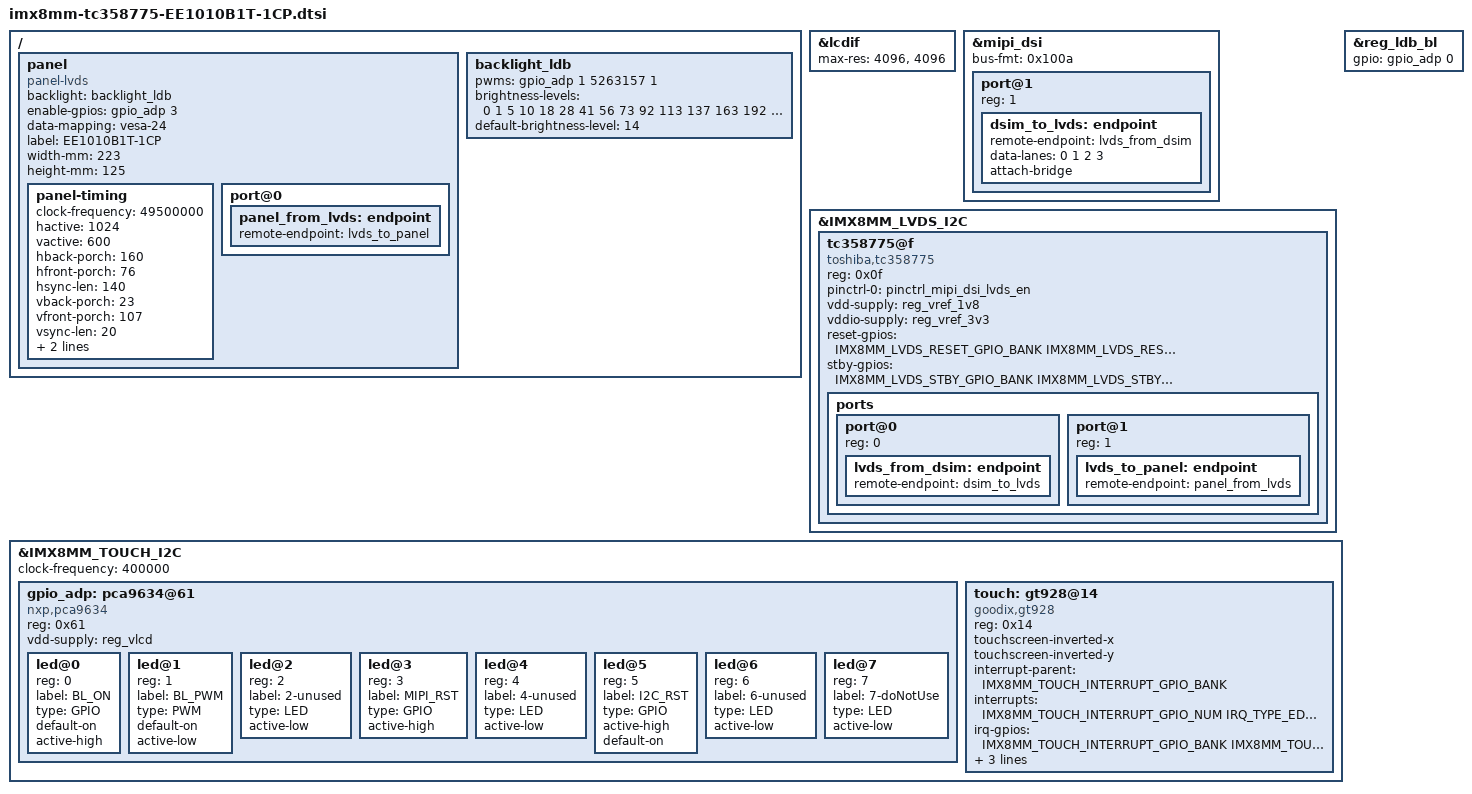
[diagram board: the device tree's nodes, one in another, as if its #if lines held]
/*
 * Copyright (C) 2024 F&S Elektronik Systeme GmbH
 *
 * This program is free software; you can redistribute it and/or modify
 * it under the terms of the GNU General Public License version 2 as
 * published by the Free Software Foundation.
 */

&lcdif {
        status = "okay";
        /* important to overwrite max-res otherwise DRM lcdif will fail to
         * find a suitable connector
         */
        max-res = <4096>, <4096>;
};

&mipi_dsi {
        status = "okay";
        bus-fmt = <0x100a>;
        port@1 {
                reg = <1>;
                dsim_to_lvds: endpoint {
                        remote-endpoint = <&lvds_from_dsim>;
                        data-lanes = <0 1 2 3>;
                        attach-bridge;
                };
        };
};

&IMX8MM_LVDS_I2C {
        tc358775@f {
                compatible = "toshiba,tc358775";
                reg = <0x0f>;
                pinctrl-names = "default";
                pinctrl-0 = <&pinctrl_mipi_dsi_lvds_en>;
                vdd-supply = <&reg_vref_1v8>;
                vddio-supply = <&reg_vref_3v3>;

                reset-gpios = <&IMX8MM_LVDS_RESET_GPIO_BANK IMX8MM_LVDS_RESET_GPIO_NUM GPIO_ACTIVE_LOW>;
#ifdef IMX8MM_LVDS_STBY_GPIO_BANK
                stby-gpios  = <&IMX8MM_LVDS_STBY_GPIO_BANK IMX8MM_LVDS_STBY_GPIO_NUM GPIO_ACTIVE_LOW>;
#endif
                ports {
                        #address-cells = <1>;
                        #size-cells = <0>;

                        port@0 {
                                reg = <0>;

                                lvds_from_dsim: endpoint {
                                        remote-endpoint = <&dsim_to_lvds>;
                                };
                        };

                        port@1 {
                                reg = <1>;

                                lvds_to_panel: endpoint {
                                        remote-endpoint = <&panel_from_lvds>;
                                };
                        };
                };
        };
};

/{
        panel: panel {
			compatible = "panel-lvds";
			backlight = <&backlight_ldb>;
			/* MIPI_RST from board */
			//enable-gpios = <&IMX8MP_MIPI_RESET_GPIO_BANK IMX8MP_MIPI_RESET_GPIO_NUM GPIO_ACTIVE_HIGH>;
			/* Mounting option for MIPI_RST on pca9634 (ADP-LVDS2LVDS2) */
			enable-gpios = <&gpio_adp 3 GPIO_ACTIVE_HIGH>;
			data-mapping = "vesa-24";
			label = "EE1010B1T-1CP";
		            width-mm = <223>;
		            height-mm = <125>;
			status = "okay";

			panel-timing {
				clock-frequency = <49500000>;
				hactive = <1024>;
				vactive = <600>;

				hback-porch = <160>;
				hfront-porch = <76>;
				hsync-len = <140>;
				vback-porch = <23>;
				vfront-porch = <107>;
				vsync-len = <20>;
				pixelclk-active = <0>;
				de-active = <1>;
			};

                port@0 {
                        panel_from_lvds: endpoint {
                                remote-endpoint = <&lvds_to_panel>;
                        };
                };
        };

        backlight_ldb: backlight_ldb {
                pwms = <&gpio_adp 1 5263157 1>;
                brightness-levels = <0 1 5 10 18 28 41 56
                                     73 92 113 137 163 192 222 255>;
                default-brightness-level = <14>;
        };
};

&reg_ldb_bl{
	gpio = <&gpio_adp 0 GPIO_ACTIVE_HIGH>;
};


&IMX8MM_TOUCH_I2C {
	clock-frequency = <400000>;
	gpio_adp: pca9634@61 {
			compatible = "nxp,pca9634";
			reg = <0x61>;
			vdd-supply = <&reg_vlcd>;
			#address-cells = <1>;
			#size-cells = <0>;
			#pwm-cells = <3>;
			#gpio-cells = <2>;
			led@0 {
				reg = <0>;
				label = "BL_ON";
				type = "GPIO";
				default-on;	        /* or: keep-value */
				active-high;
			};
			led@1 {
				reg = <1>;
				label = "BL_PWM";
				type = "PWM";
				default-on;             /* or: keep-value */
				active-low;
			};
			led@2 {
				reg = <2>;
				label = "2-unused";
				type = "LED";
				active-low;
			};
			led@3 {
				reg = <3>;
				label = "MIPI_RST";
				type = "GPIO";
				active-high;
			};
			led@4 {
				reg = <4>;
				label = "4-unused";
				type = "LED";
				active-low;
			};
			led@5 {
				reg = <5>;
				label = "I2C_RST";
				type = "GPIO";
				active-high;
				default-on;     /* or: keep-value */
			};
			led@6 {
				reg = <6>;
				label = "6-unused";
				type = "LED";
				active-low;
			};
            led@7 {
                    reg = <7>;
                    label = "7-doNotUse";
                    type = "LED";
                    active-low;
            };
		};
        /* GOODIX PCAP touch on Touch-Connector (I2C) */
        touch: gt928@14 {
                compatible = "goodix,gt928";
                reg = <0x14>;
                //vdd-supply = <&reg_vlcd>;
                touchscreen-inverted-x;
                touchscreen-inverted-y;
                interrupt-parent = <&IMX8MM_TOUCH_INTERRUPT_GPIO_BANK>;
                interrupts = <IMX8MM_TOUCH_INTERRUPT_GPIO_NUM IRQ_TYPE_EDGE_RISING>;
                irq-gpios = <&IMX8MM_TOUCH_INTERRUPT_GPIO_BANK IMX8MM_TOUCH_INTERRUPT_GPIO_NUM GPIO_ACTIVE_HIGH>;
                touchscreen-size-x = <1024>;
                touchscreen-size-y = <600>;
                reset-gpios = <&gpio_adp 5 GPIO_ACTIVE_HIGH>;
        };
};
